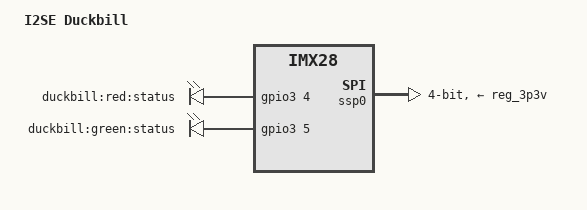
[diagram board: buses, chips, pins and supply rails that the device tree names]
/*
 * Copyright (C) 2013-2014 Michael Heimpold <mhei@heimpold.de>
 * Copyright (C) 2015 I2SE GmbH <info@i2se.com>
 *
 * The code contained herein is licensed under the GNU General Public
 * License. You may obtain a copy of the GNU General Public License
 * Version 2 or later at the following locations:
 *
 * http://www.opensource.org/licenses/gpl-license.html
 * http://www.gnu.org/copyleft/gpl.html
 */

#include <dt-bindings/gpio/gpio.h>
#include "imx28-duckbill.dtsi"

/ {
	model = "I2SE Duckbill";
	compatible = "i2se,duckbill", "fsl,imx28";

	apb@80000000 {
		apbh@80000000 {
			ssp0: ssp@80010000 {
				compatible = "fsl,imx28-mmc";
				pinctrl-names = "default";
				pinctrl-0 = <&mmc0_4bit_pins_a
					&mmc0_cd_cfg &mmc0_sck_cfg>;
				bus-width = <4>;
				vmmc-supply = <&reg_3p3v>;
				status = "okay";
			};

			pinctrl@80018000 {
				mac0_phy_reset_pin: mac0_phy_reset_pin@0 {
					reg = <0>;
					fsl,pinmux-ids = <
						MX28_PAD_SSP0_DATA7__GPIO_2_7    /* PHY Reset */
					>;
					fsl,drive-strength = <MXS_DRIVE_4mA>;
					fsl,voltage = <MXS_VOLTAGE_HIGH>;
					fsl,pull-up = <MXS_PULL_DISABLE>;
				};

				status_led_pins: status_led_pins@0 {
					reg = <0>;
					fsl,pinmux-ids = <
						MX28_PAD_AUART1_RX__GPIO_3_4
						MX28_PAD_AUART1_TX__GPIO_3_5
					>;
					fsl,drive-strength = <MXS_DRIVE_4mA>;
					fsl,voltage = <MXS_VOLTAGE_HIGH>;
					fsl,pull-up = <MXS_PULL_DISABLE>;
				};
			};
		};
	};

	ahb@80080000 {
		mac0: ethernet@800f0000 {
			phy-reset-gpios = <&gpio2 7 GPIO_ACTIVE_LOW>;
		};
	};

	leds {
		compatible = "gpio-leds";
		pinctrl-names = "default";
		pinctrl-0 = <&status_led_pins>;

		status_red {
			label = "duckbill:red:status";
			gpios = <&gpio3 4 GPIO_ACTIVE_HIGH>;
			linux,default-trigger = "default-on";
		};

		status_green {
			label = "duckbill:green:status";
			gpios = <&gpio3 5 GPIO_ACTIVE_HIGH>;
			linux,default-trigger = "heartbeat";
		};
	};
};
